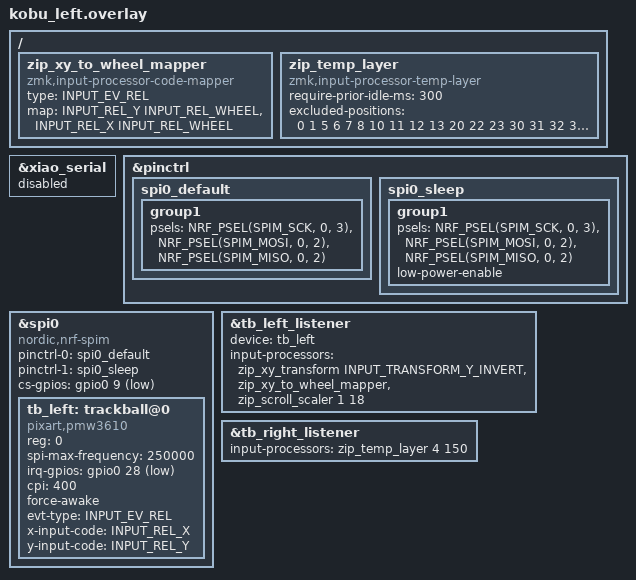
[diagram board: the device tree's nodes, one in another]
/*
 * kobu LEFT half = central.
 *
 *   - Local PMW3610 (tb_left) drives VERTICAL SCROLL. BOTH roll axes feed the
 *     vertical wheel (custom zip_xy_to_wheel_mapper folds REL_X and REL_Y onto
 *     REL_WHEEL; horizontal/pan scroll intentionally removed): roll UP = scroll
 *     UP, roll DOWN = scroll DOWN, roll RIGHT = scroll UP, roll LEFT = scroll
 *     DOWN. Y is inverted (INPUT_TRANSFORM_Y_INVERT before the mapper) so that
 *     up=up and the up+right / down+left diagonal adds instead of cancelling.
 *     ~18 raw counts per scroll line. (Was 2D X->HWHEEL/Y->WHEEL; user asked for
 *     right=up / left=down instead of horizontal pan, then for up=up + stronger
 *     diagonal — see the &tb_left_listener block for the dead-diagonal note.)
 *   - Consumes the RIGHT half's forwarded pointer via tb_right_listener and
 *     runs the auto-mouse temp-layer (layer 4) on it (matches the RMK
 *     run_auto_mouse_layer: AUTO_MOUSE_LAYER=4, TIMEOUT=150ms, PRIOR_IDLE=300ms).
 *
 * SPI (3-wire PMW3610): SCLK=P0_03(D1), SDIO(MOSI=MISO)=P0_02(D0), CS=P0_09(NFC1).
 * The badjeff driver requires irq-gpios -> wire MOTION=P0_28(D2). (The RMK
 * firmware polls and ignores MOTION, but the line is physically present.)
 */

#include "kobu.dtsi"
#include <zephyr/dt-bindings/input/input-event-codes.h>
#include <input/processors.dtsi>
#include <dt-bindings/zmk/input_transform.h>

&xiao_serial { status = "disabled"; };

&pinctrl {
    spi0_default: spi0_default {
        group1 {
            psels = <NRF_PSEL(SPIM_SCK,  0, 3)>,
                    <NRF_PSEL(SPIM_MOSI, 0, 2)>,
                    <NRF_PSEL(SPIM_MISO, 0, 2)>;
        };
    };
    spi0_sleep: spi0_sleep {
        group1 {
            psels = <NRF_PSEL(SPIM_SCK,  0, 3)>,
                    <NRF_PSEL(SPIM_MOSI, 0, 2)>,
                    <NRF_PSEL(SPIM_MISO, 0, 2)>;
            low-power-enable;
        };
    };
};

&spi0 {
    status = "okay";
    compatible = "nordic,nrf-spim";
    pinctrl-0 = <&spi0_default>;
    pinctrl-1 = <&spi0_sleep>;
    pinctrl-names = "default", "sleep";
    cs-gpios = <&gpio0 9 GPIO_ACTIVE_LOW>;   /* P0_09 (NFC1) = NCS */

    tb_left: trackball@0 {
        status = "okay";
        compatible = "pixart,pmw3610";
        reg = <0>;
        spi-max-frequency = <250000>;    /* kobu: 250 kHz. 2 MHz floated to 0xFF on this marginal LEFT 3-wire SDIO; 1 MHz / 500 kHz still let partial SIGN-flip glitches through (occasional wrong-direction scroll tick). Pure-IRQ (poll off) so clock doesn't affect slow-roll response — drop to 250 kHz to cut the glitch rate further at the source. Burst ~224 us, negligible. HW-confirmed improvement 2026-06-05 (user). */
        irq-gpios = <&gpio0 28 (GPIO_ACTIVE_LOW | GPIO_PULL_UP)>;  /* P0_28 = MOTION (D2) */
        cpi = <400>;          /* LEFT scroll ball: calmer scroll (user 2026-06-06; was 600 from keyboard.toml). PMW3610 CPI is quantized to 200-cpi steps (cpi/200), so 400 = one step below 600 (200 is the next step down). INDEPENDENT of the RIGHT pointer CPI, which is set on its own tb_right node in kobu_right.overlay. */
        force-awake;          /* = RMK force_awake=true (continuous tracking) */

        evt-type = <INPUT_EV_REL>;
        x-input-code = <INPUT_REL_X>;
        y-input-code = <INPUT_REL_Y>;
    };
};

/ {
    /* Custom scroll mapper: fold BOTH roll axes onto the VERTICAL wheel.
     *   REL_Y -> WHEEL is byte-identical to the stock zip_xy_to_scroll_mapper's
     *     vertical mapping, so up/down roll scrolls vertically exactly as today.
     *   REL_X -> WHEEL (instead of the stock X -> HWHEEL) makes left/right roll
     *     scroll vertically too. The code-mapper preserves value/sign, and kobu's
     *     convention is roll-right = +REL_X = WHEEL+ = scroll-up (RMK
     *     trackball.rs ScrollProcessor, scroll_invert_x=false), so roll-right =
     *     scroll-up and roll-left = scroll-down. Horizontal/pan scroll is gone.
     * The downstream zip_scroll_scaler carries ONE remainder over the merged
     * WHEEL stream (both axes share remainders->wheel, exactly as it already does
     * across successive REL_Y events) -> total = sum(dx+dy)/18, no counts lost. */
    zip_xy_to_wheel_mapper: zip_xy_to_wheel_mapper {
        compatible = "zmk,input-processor-code-mapper";
        #input-processor-cells = <0>;
        type = <INPUT_EV_REL>;
        map
            = <INPUT_REL_Y INPUT_REL_WHEEL>
            , <INPUT_REL_X INPUT_REL_WHEEL>
            ;
    };

    /* Auto-mouse layer (RIGHT ball). layer=4, idle-deactivate=150ms,
     * require-prior-idle=300ms. Pressing keys NOT in excluded-positions drops
     * the layer; the excluded set keeps the layer alive for everything you use
     * WHILE mousing (the layer-4 mouse buttons + the command keys kobu added
     * for cmd-tab-while-mousing + all thumbs), so only reaching back to type a
     * letter (or the 150ms idle) ends it. */
    /omit-if-no-ref/ zip_temp_layer: zip_temp_layer {
        compatible = "zmk,input-processor-temp-layer";
        #input-processor-cells = <2>;
        require-prior-idle-ms = <300>;
    };
};

&tb_left_listener {
    status = "okay";
    device = <&tb_left>;
    input-processors =
        <&zip_xy_transform INPUT_TRANSFORM_Y_INVERT>,  /* HW-confirmed: roll-up read as -WHEEL -> negate RAW REL_Y so roll-up = scroll-up. X (roll-right = scroll-up) is left alone. MUST be first (acts on REL_Y before the mapper folds it to REL_WHEEL). */
        <&zip_xy_to_wheel_mapper>,       /* BOTH axes -> vertical wheel: roll-up = scroll-up, roll-right = scroll-up */
        <&zip_scroll_scaler 1 18>;       /* ~18 raw counts per scroll line (single carried remainder over the merged WHEEL stream) */
        /* HW-confirmed directions (user, 2026-06-06): roll-right = scroll-up was
         * already correct; roll-up/down was REVERSED -> fixed by Y_INVERT above.
         * Now both axes push the wheel the same way, so the up+right / down+left
         * diagonal is ADDITIVE (strong). Inherent trade-off: folding two axes into
         * ONE vertical wheel (no horizontal scroll, by spec) always leaves exactly
         * one DEAD diagonal — here up+left / down+right, where the X intent
         * (left=down / right=up) opposes the Y intent (up=up / down=down) and they
         * cancel. This is unavoidable with stock ZMK linear processors, not a bug.
         * (To flip the X axis instead, swap to INPUT_TRANSFORM_X_INVERT; both must
         * stay BEFORE the mapper. OS "natural scrolling" flips perceived vertical.) */
};

&tb_right_listener {
    status = "okay";
    input-processors = <&zip_temp_layer 4 150>;
};

&zip_temp_layer {
    /* positions (row*10+col): layer-4 mouse buttons 5,6,7,8; layer-4 command
     * keys 0,1,10,11,12,13,20,22,23 (brackets, TD2, Tab, LGui, LCtrl, C, V);
     * all thumbs 30..39. Everything else (transparent letter columns) ends the
     * mouse layer when pressed = "back to typing". */
    excluded-positions = <
        0  1
        5  6  7  8
        10 11 12 13
        20 22 23
        30 31 32 33 34 35 36 37 38 39
    >;
};
